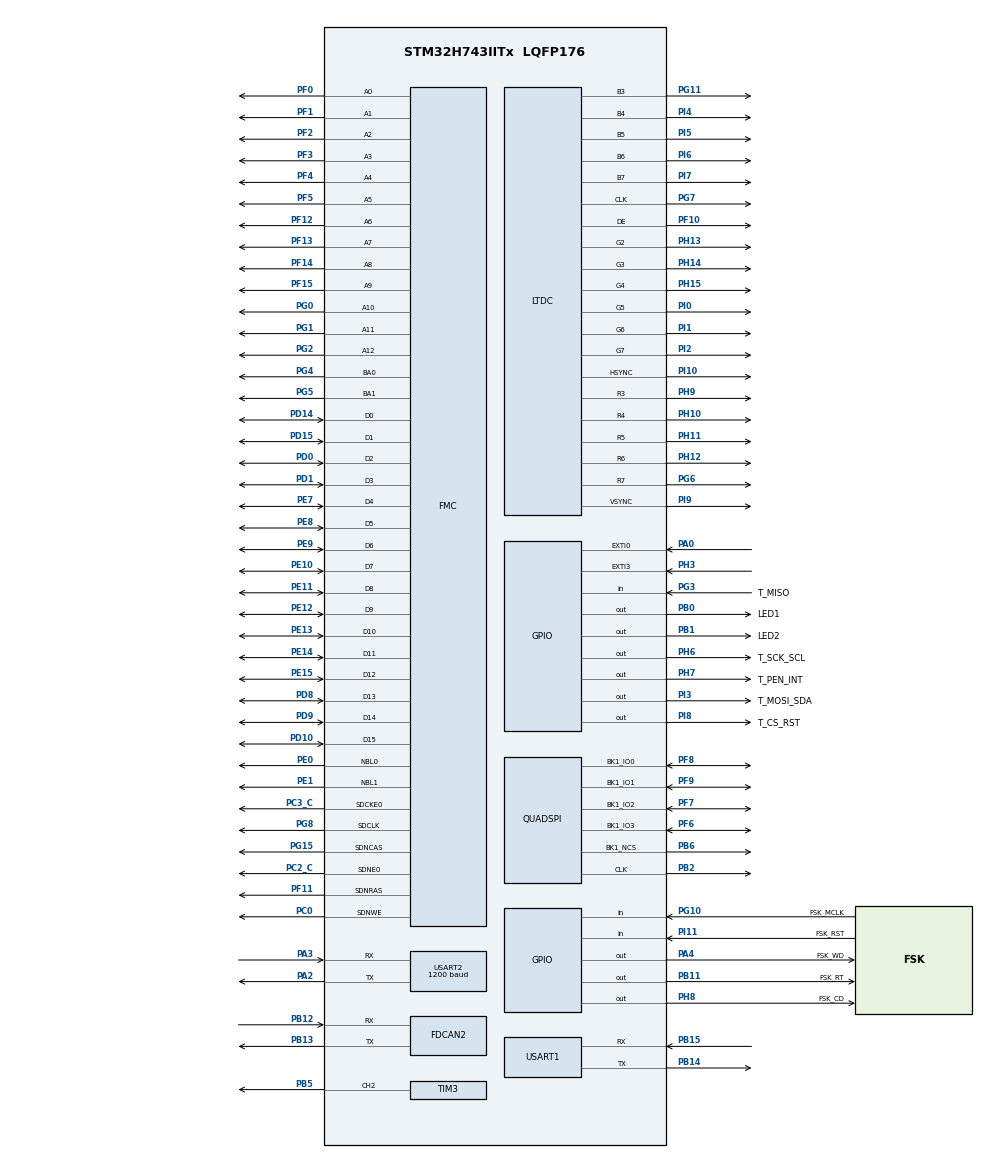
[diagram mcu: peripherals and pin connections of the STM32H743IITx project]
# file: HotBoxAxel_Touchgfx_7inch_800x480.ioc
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CORTEX_M7.AccessPermission-Cortex_Memory_Protection_Unit_Region1_Settings=MPU_REGION_FULL_ACCESS
CORTEX_M7.AccessPermission-Cortex_Memory_Protection_Unit_Region2_Settings=MPU_REGION_FULL_ACCESS
CORTEX_M7.AccessPermission-Cortex_Memory_Protection_Unit_Region3_Settings=MPU_REGION_FULL_ACCESS
CORTEX_M7.AccessPermission-Cortex_Memory_Protection_Unit_Region4_Settings=MPU_REGION_FULL_ACCESS
CORTEX_M7.AccessPermission-Cortex_Memory_Protection_Unit_Region5_Settings=MPU_REGION_FULL_ACCESS
CORTEX_M7.AccessPermission-Cortex_Memory_Protection_Unit_Region6_Settings=MPU_REGION_FULL_ACCESS
CORTEX_M7.AccessPermission-Cortex_Memory_Protection_Unit_Region7_Settings=MPU_REGION_FULL_ACCESS
CORTEX_M7.BaseAddress-Cortex_Memory_Protection_Unit_Region1_Settings=0x90000000
CORTEX_M7.BaseAddress-Cortex_Memory_Protection_Unit_Region2_Settings=0xC0000000
CORTEX_M7.BaseAddress-Cortex_Memory_Protection_Unit_Region3_Settings=0x20000000
CORTEX_M7.BaseAddress-Cortex_Memory_Protection_Unit_Region4_Settings=0x24000000
CORTEX_M7.BaseAddress-Cortex_Memory_Protection_Unit_Region5_Settings=0x30000000
CORTEX_M7.BaseAddress-Cortex_Memory_Protection_Unit_Region6_Settings=0x38000000
CORTEX_M7.BaseAddress-Cortex_Memory_Protection_Unit_Region7_Settings=0x60000000
CORTEX_M7.CPU_DCache=Enabled
CORTEX_M7.CPU_ICache=Enabled
CORTEX_M7.DisableExec-Cortex_Memory_Protection_Unit_Region0_Settings=MPU_INSTRUCTION_ACCESS_DISABLE
CORTEX_M7.DisableExec-Cortex_Memory_Protection_Unit_Region2_Settings=MPU_INSTRUCTION_ACCESS_ENABLE
CORTEX_M7.Enable-Cortex_Memory_Protection_Unit_Region0_Settings=MPU_REGION_ENABLE
CORTEX_M7.Enable-Cortex_Memory_Protection_Unit_Region1_Settings=MPU_REGION_ENABLE
CORTEX_M7.Enable-Cortex_Memory_Protection_Unit_Region2_Settings=MPU_REGION_ENABLE
CORTEX_M7.Enable-Cortex_Memory_Protection_Unit_Region3_Settings=MPU_REGION_ENABLE
CORTEX_M7.Enable-Cortex_Memory_Protection_Unit_Region4_Settings=MPU_REGION_ENABLE
CORTEX_M7.Enable-Cortex_Memory_Protection_Unit_Region5_Settings=MPU_REGION_ENABLE
CORTEX_M7.Enable-Cortex_Memory_Protection_Unit_Region6_Settings=MPU_REGION_ENABLE
CORTEX_M7.Enable-Cortex_Memory_Protection_Unit_Region7_Settings=MPU_REGION_ENABLE
CORTEX_M7.Enable-Cortex_Memory_Protection_Unit_Region8_Settings=__NULL
CORTEX_M7.IsBufferable-Cortex_Memory_Protection_Unit_Region2_Settings=MPU_ACCESS_BUFFERABLE
CORTEX_M7.IsBufferable-Cortex_Memory_Protection_Unit_Region3_Settings=MPU_ACCESS_BUFFERABLE
CORTEX_M7.IsBufferable-Cortex_Memory_Protection_Unit_Region4_Settings=MPU_ACCESS_BUFFERABLE
CORTEX_M7.IsBufferable-Cortex_Memory_Protection_Unit_Region5_Settings=MPU_ACCESS_BUFFERABLE
CORTEX_M7.IsBufferable-Cortex_Memory_Protection_Unit_Region6_Settings=MPU_ACCESS_BUFFERABLE
CORTEX_M7.IsCacheable-Cortex_Memory_Protection_Unit_Region1_Settings=MPU_ACCESS_CACHEABLE
CORTEX_M7.IsCacheable-Cortex_Memory_Protection_Unit_Region2_Settings=MPU_ACCESS_CACHEABLE
CORTEX_M7.IsCacheable-Cortex_Memory_Protection_Unit_Region3_Settings=MPU_ACCESS_CACHEABLE
CORTEX_M7.IsCacheable-Cortex_Memory_Protection_Unit_Region4_Settings=MPU_ACCESS_CACHEABLE
CORTEX_M7.IsCacheable-Cortex_Memory_Protection_Unit_Region5_Settings=MPU_ACCESS_CACHEABLE
CORTEX_M7.IsCacheable-Cortex_Memory_Protection_Unit_Region6_Settings=MPU_ACCESS_CACHEABLE
CORTEX_M7.IsShareable-Cortex_Memory_Protection_Unit_Region0_Settings=MPU_ACCESS_SHAREABLE
CORTEX_M7.MPU_Control=__NULL
CORTEX_M7.Size-Cortex_Memory_Protection_Unit_Region0_Settings=MPU_REGION_SIZE_4GB
CORTEX_M7.Size-Cortex_Memory_Protection_Unit_Region1_Settings=MPU_REGION_SIZE_32MB
CORTEX_M7.Size-Cortex_Memory_Protection_Unit_Region2_Settings=MPU_REGION_SIZE_32MB
CORTEX_M7.Size-Cortex_Memory_Protection_Unit_Region3_Settings=MPU_REGION_SIZE_128KB
CORTEX_M7.Size-Cortex_Memory_Protection_Unit_Region4_Settings=MPU_REGION_SIZE_512KB
CORTEX_M7.Size-Cortex_Memory_Protection_Unit_Region5_Settings=MPU_REGION_SIZE_512KB
CORTEX_M7.Size-Cortex_Memory_Protection_Unit_Region6_Settings=MPU_REGION_SIZE_64KB
CORTEX_M7.Size-Cortex_Memory_Protection_Unit_Region7_Settings=MPU_REGION_SIZE_64KB
CORTEX_M7.SubRegionDisable-Cortex_Memory_Protection_Unit_Region0_Settings=0x87
DMA2D.ColorMode=DMA2D_OUTPUT_RGB565
FDCAN2.CalculateBaudRateNominal=520833
FDCAN2.CalculateTimeBitNominal=1920
FDCAN2.CalculateTimeQuantumNominal=640.0
FMC.CASLatency1=FMC_SDRAM_CAS_LATENCY_3
FMC.ColumnBitsNumber1=FMC_SDRAM_COLUMN_BITS_NUM_9
FMC.ExitSelfRefreshDelay1=7
FMC.LoadToActiveDelay1=2
FMC.RCDDelay1=2
FMC.RPDelay1=2
FMC.ReadBurst1=FMC_SDRAM_RBURST_ENABLE
FMC.ReadPipeDelay1=FMC_SDRAM_RPIPE_DELAY_0
FMC.RowCycleDelay1=7
FMC.SDClockPeriod1=FMC_SDRAM_CLOCK_PERIOD_2
FMC.SelfRefreshTime1=4
FMC.WriteRecoveryTime1=3
LTDC.ActiveW=800
LTDC.Alpha_L0=255
LTDC.BlendingFactor1_L0=LTDC_BLENDING_FACTOR1_CA
LTDC.BlendingFactor2_L0=LTDC_BLENDING_FACTOR2_CA
LTDC.FBStartAdress_L0=0xC0000000
LTDC.HBP=46
LTDC.HFP=198
LTDC.HSync=2
LTDC.ImageHeight_L0=480
LTDC.ImageWidth_L0=800
LTDC.Layers=0
LTDC.PixelFormat_L0=LTDC_PIXEL_FORMAT_RGB565
LTDC.VBP=23
LTDC.VFP=15
LTDC.VSync=2
LTDC.WindowX1_L0=800
LTDC.WindowY1_L0=480
Mcu.Family=STM32H7
Mcu.Name=STM32H743IITx
Mcu.Package=LQFP176
NVIC.DMA2D_IRQn=true\:5\:0\:true\:false\:true\:true\:true\:true
NVIC.EXTI0_IRQn=true\:6\:0\:true\:false\:true\:true\:true\:true
NVIC.EXTI3_IRQn=true\:6\:0\:true\:false\:true\:true\:true\:true
NVIC.LTDC_ER_IRQn=true\:0\:0\:false\:false\:true\:true\:true\:true
NVIC.LTDC_IRQn=true\:5\:0\:true\:false\:true\:true\:true\:true
NVIC.PriorityGroup=NVIC_PRIORITYGROUP_4
NVIC.USART2_IRQn=true\:0\:0\:false\:false\:true\:true\:true\:true
PA0.GPIO_ModeDefaultEXTI=GPIO_MODE_IT_RISING
PA0.Signal=GPXTI0
PA13\ (JTMS/SWDIO).Mode=Serial_Wire
PA13\ (JTMS/SWDIO).Signal=DEBUG_JTMS-SWDIO
PA14\ (JTCK/SWCLK).Mode=Serial_Wire
PA14\ (JTCK/SWCLK).Signal=DEBUG_JTCK-SWCLK
PA2.Mode=Asynchronous
PA2.Signal=USART2_TX
PA3.Mode=Asynchronous
PA3.Signal=USART2_RX
PA4.GPIO_Label=FSK_WD
PA4.Signal=GPIO_Output
PB0.GPIO_Label=LED1
PB0.GPIO_Speed=GPIO_SPEED_FREQ_VERY_HIGH
PB0.PinState=GPIO_PIN_RESET
PB0.Signal=GPIO_Output
PB1.GPIO_Label=LED2
PB1.GPIO_Speed=GPIO_SPEED_FREQ_VERY_HIGH
PB1.Signal=GPIO_Output
PB11.GPIO_Label=FSK_RT
PB11.Signal=GPIO_Output
PB12.GPIO_PuPd=GPIO_PULLUP
PB12.GPIO_Speed=GPIO_SPEED_FREQ_MEDIUM
PB12.Mode=FDCAN_Activate
PB12.Signal=FDCAN2_RX
PB13.Mode=FDCAN_Activate
PB13.Signal=FDCAN2_TX
PB14.Mode=Asynchronous
PB14.Signal=USART1_TX
PB15.Mode=Asynchronous
PB15.Signal=USART1_RX
PB2.GPIO_Speed=GPIO_SPEED_FREQ_VERY_HIGH
PB2.Mode=Single Bank 1
PB2.Signal=QUADSPI_CLK
PB5.Signal=S_TIM3_CH2
PB6.GPIO_FM6=SYSCFG_PMCR_I2C_PB6_FMP
PB6.GPIO_Speed=GPIO_SPEED_FREQ_VERY_HIGH
PB6.Mode=Single Bank 1
PB6.Signal=QUADSPI_BK1_NCS
PC0.Signal=FMC_SDNWE
PC14-OSC32_IN\ (OSC32_IN).Mode=LSE-External-Oscillator
PC14-OSC32_IN\ (OSC32_IN).Signal=RCC_OSC32_IN
PC15-OSC32_OUT\ (OSC32_OUT).Mode=LSE-External-Oscillator
PC15-OSC32_OUT\ (OSC32_OUT).Signal=RCC_OSC32_OUT
PC2_C.Mode=SdramChipSelect1_1
PC2_C.Signal=FMC_SDNE0
PC3_C.Mode=SdramChipSelect1_1
PC3_C.Signal=FMC_SDCKE0
PD0.Signal=FMC_D2_DA2
PD1.Signal=FMC_D3_DA3
PD10.Signal=FMC_D15_DA15
PD11.Signal=FMC_A16_CLE
PD12.Signal=FMC_A17_ALE
PD13.Signal=FMC_A18
PD14.Signal=FMC_D0_DA0
PD15.Signal=FMC_D1_DA1
PD6.Signal=LTDC_B2
PD8.Signal=FMC_D13_DA13
PD9.Signal=FMC_D14_DA14
PE0.Signal=FMC_NBL0
PE1.Signal=FMC_NBL1
PE10.Signal=FMC_D7_DA7
PE11.Signal=FMC_D8_DA8
PE12.Signal=FMC_D9_DA9
PE13.Signal=FMC_D10_DA10
PE14.Signal=FMC_D11_DA11
PE15.Signal=FMC_D12_DA12
PE7.Signal=FMC_D4_DA4
PE8.Signal=FMC_D5_DA5
PE9.Signal=FMC_D6_DA6
PF0.Signal=FMC_A0
PF1.Signal=FMC_A1
PF10.GPIO_Speed=GPIO_SPEED_FREQ_VERY_HIGH
PF10.Mode=RGB565
PF10.Signal=LTDC_DE
PF11.Signal=FMC_SDNRAS
PF12.Signal=FMC_A6
PF13.Signal=FMC_A7
PF14.Signal=FMC_A8
PF15.Signal=FMC_A9
PF2.Signal=FMC_A2
PF3.Signal=FMC_A3
PF4.Signal=FMC_A4
PF5.Signal=FMC_A5
PF6.GPIO_Speed=GPIO_SPEED_FREQ_VERY_HIGH
PF6.Mode=Single Bank 1
PF6.Signal=QUADSPI_BK1_IO3
PF7.GPIO_Speed=GPIO_SPEED_FREQ_VERY_HIGH
PF7.Mode=Single Bank 1
PF7.Signal=QUADSPI_BK1_IO2
PF8.GPIO_Speed=GPIO_SPEED_FREQ_VERY_HIGH
PF8.Mode=Single Bank 1
PF8.Signal=QUADSPI_BK1_IO0
PF9.GPIO_Speed=GPIO_SPEED_FREQ_VERY_HIGH
PF9.Mode=Single Bank 1
PF9.Signal=QUADSPI_BK1_IO1
PG0.Signal=FMC_A10
PG1.Signal=FMC_A11
PG10.GPIO_Label=FSK_MCLK
PG10.Signal=GPIO_Input
PG11.GPIO_Speed=GPIO_SPEED_FREQ_VERY_HIGH
PG11.Mode=RGB565
PG11.Signal=LTDC_B3
PG12.Signal=LTDC_B1
PG14.Signal=LTDC_B0
PG15.Signal=FMC_SDNCAS
PG2.Signal=FMC_A12
PG3.GPIO_Label=T_MISO
PG3.GPIO_PuPd=GPIO_NOPULL
PG3.Signal=GPIO_Input
PG4.Signal=FMC_A14_BA0
PG5.Signal=FMC_A15_BA1
PG6.GPIO_Speed=GPIO_SPEED_FREQ_VERY_HIGH
PG6.Mode=RGB565
PG6.Signal=LTDC_R7
PG7.GPIO_Speed=GPIO_SPEED_FREQ_VERY_HIGH
PG7.Mode=RGB565
PG7.Signal=LTDC_CLK
PG8.Signal=FMC_SDCLK
PH0-OSC_IN\ (PH0).Mode=HSE-External-Oscillator
PH0-OSC_IN\ (PH0).Signal=RCC_OSC_IN
PH1-OSC_OUT\ (PH1).Mode=HSE-External-Oscillator
PH1-OSC_OUT\ (PH1).Signal=RCC_OSC_OUT
PH10.GPIO_Speed=GPIO_SPEED_FREQ_VERY_HIGH
PH10.Mode=RGB565
PH10.Signal=LTDC_R4
PH11.GPIO_Speed=GPIO_SPEED_FREQ_VERY_HIGH
PH11.Mode=RGB565
PH11.Signal=LTDC_R5
PH12.GPIO_Speed=GPIO_SPEED_FREQ_VERY_HIGH
PH12.Mode=RGB565
PH12.Signal=LTDC_R6
PH13.GPIO_Speed=GPIO_SPEED_FREQ_VERY_HIGH
PH13.Mode=RGB565
PH13.Signal=LTDC_G2
PH14.GPIO_Speed=GPIO_SPEED_FREQ_VERY_HIGH
PH14.Mode=RGB565
PH14.Signal=LTDC_G3
PH15.GPIO_Speed=GPIO_SPEED_FREQ_VERY_HIGH
PH15.Mode=RGB565
PH15.Signal=LTDC_G4
PH3.GPIO_ModeDefaultEXTI=GPIO_MODE_IT_FALLING
PH3.Signal=GPXTI3
PH6.GPIO_Label=T_SCK_SCL
PH6.GPIO_ModeDefaultOutputPP=GPIO_MODE_OUTPUT_OD
PH6.GPIO_PuPd=GPIO_NOPULL
PH6.GPIO_Speed=GPIO_SPEED_FREQ_LOW
PH6.PinState=GPIO_PIN_SET
PH6.Signal=GPIO_Output
PH7.GPIO_Label=T_PEN_INT
PH7.GPIO_PuPd=GPIO_NOPULL
PH7.Signal=GPIO_Output
PH8.GPIO_Label=FSK_CD
PH8.Signal=GPIO_Output
PH9.GPIO_Speed=GPIO_SPEED_FREQ_VERY_HIGH
PH9.Mode=RGB565
PH9.Signal=LTDC_R3
PI0.GPIO_Speed=GPIO_SPEED_FREQ_VERY_HIGH
PI0.Mode=RGB565
PI0.Signal=LTDC_G5
PI1.GPIO_Speed=GPIO_SPEED_FREQ_VERY_HIGH
PI1.Mode=RGB565
PI1.Signal=LTDC_G6
PI10.GPIO_Speed=GPIO_SPEED_FREQ_VERY_HIGH
PI10.Mode=RGB565
PI10.Signal=LTDC_HSYNC
PI11.GPIO_Label=FSK_RST
PI11.Signal=GPIO_Input
PI2.GPIO_Speed=GPIO_SPEED_FREQ_VERY_HIGH
PI2.Mode=RGB565
PI2.Signal=LTDC_G7
PI3.GPIO_Label=T_MOSI_SDA
PI3.GPIO_ModeDefaultOutputPP=GPIO_MODE_OUTPUT_OD
PI3.GPIO_PuPd=GPIO_NOPULL
PI3.GPIO_Speed=GPIO_SPEED_FREQ_LOW
PI3.PinState=GPIO_PIN_RESET
PI3.Signal=GPIO_Output
PI4.GPIO_Speed=GPIO_SPEED_FREQ_VERY_HIGH
PI4.Mode=RGB565
PI4.Signal=LTDC_B4
PI5.GPIO_Speed=GPIO_SPEED_FREQ_VERY_HIGH
PI5.Mode=RGB565
PI5.Signal=LTDC_B5
PI6.GPIO_Speed=GPIO_SPEED_FREQ_VERY_HIGH
PI6.Mode=RGB565
PI6.Signal=LTDC_B6
PI7.GPIO_Speed=GPIO_SPEED_FREQ_VERY_HIGH
PI7.Mode=RGB565
PI7.Signal=LTDC_B7
PI8.GPIO_Label=T_CS_RST
PI8.Signal=GPIO_Output
PI9.GPIO_Speed=GPIO_SPEED_FREQ_VERY_HIGH
PI9.Mode=RGB565
PI9.Signal=LTDC_VSYNC
ProjectManager.HeapSize=0x1000
ProjectManager.StackSize=0x2000
ProjectManager.TargetToolchain=STM32CubeIDE
QUADSPI.ClockMode=QSPI_CLOCK_MODE_3
QUADSPI.ClockPrescaler=4
QUADSPI.FifoThreshold=4
QUADSPI.FlashSize=22
QUADSPI.SampleShifting=QSPI_SAMPLE_SHIFTING_HALFCYCLE
RCC.ADCFreq_Value=133000000
RCC.APB1Freq_Value=60000000
RCC.APB2Freq_Value=120000000
RCC.APB3Freq_Value=120000000
RCC.APB4Freq_Value=120000000
RCC.CortexFreq_Value=480000000
RCC.D1PPRE=RCC_APB3_DIV2
RCC.D2PPRE1=RCC_APB1_DIV4
RCC.D2PPRE2=RCC_APB2_DIV2
RCC.D3PPRE=RCC_APB4_DIV2
RCC.DIVM1=5
RCC.DIVM2=25
RCC.DIVM3=25
RCC.DIVN1=192
RCC.DIVN2=266
RCC.DIVN3=330
RCC.DIVQ1=10
RCC.DIVR3=10
RCC.FDCANCLockSelection=RCC_FDCANCLKSOURCE_HSE
RCC.FMCCLockSelection=RCC_FMCCLKSOURCE_PLL2
RCC.HCLKFreq_Value=240000000
RCC.HPRE=RCC_HCLK_DIV2
RCC.PLL1_VCI_Range-AdvancedSettings=RCC_PLL1VCIRANGE_1
RCC.PLL2FRACN=0
RCC.PLL2_VCI_Range-AdvancedSettings=RCC_PLL2VCIRANGE_3
RCC.PLL3FRACN=0
RCC.PLLFRACN=0
RCC.PLLSourceVirtual=RCC_PLLSOURCE_HSE
RCC.PWR_Regulator_Voltage_Scale=PWR_REGULATOR_VOLTAGE_SCALE0
RCC.QSPICLockSelection=RCC_QSPICLKSOURCE_PLL
RCC.RTCClockSelection=RCC_RTCCLKSOURCE_LSE
RCC.SYSCLKFreq_VALUE=480000000
RCC.SYSCLKSource=RCC_SYSCLKSOURCE_PLLCLK
RCC.USBFreq_Value=96000000
SH.FMC_A0.0=FMC_A0,13b-sda1
SH.FMC_A1.0=FMC_A1,13b-sda1
SH.FMC_A10.0=FMC_A10,13b-sda1
SH.FMC_A11.0=FMC_A11,13b-sda1
SH.FMC_A12.0=FMC_A12,13b-sda1
SH.FMC_A14_BA0.0=FMC_BA0,FourSdramBanks1
SH.FMC_A15_BA1.0=FMC_BA1,FourSdramBanks1
SH.FMC_A16_CLE.0=FMC_CLE
SH.FMC_A16_CLE.1=FMC_A16
SH.FMC_A17_ALE.0=FMC_A17
SH.FMC_A17_ALE.1=FMC_ALE
SH.FMC_A18.0=FMC_A18
SH.FMC_A2.0=FMC_A2,13b-sda1
SH.FMC_A3.0=FMC_A3,13b-sda1
SH.FMC_A4.0=FMC_A4,13b-sda1
SH.FMC_A5.0=FMC_A5,13b-sda1
SH.FMC_A6.0=FMC_A6,13b-sda1
SH.FMC_A7.0=FMC_A7,13b-sda1
SH.FMC_A8.0=FMC_A8,13b-sda1
SH.FMC_A9.0=FMC_A9,13b-sda1
SH.FMC_D0_DA0.0=FMC_D0,sd-16b-d1
SH.FMC_D10_DA10.0=FMC_D10,sd-16b-d1
SH.FMC_D11_DA11.0=FMC_D11,sd-16b-d1
SH.FMC_D12_DA12.0=FMC_D12,sd-16b-d1
SH.FMC_D13_DA13.0=FMC_D13,sd-16b-d1
SH.FMC_D14_DA14.0=FMC_D14,sd-16b-d1
SH.FMC_D15_DA15.0=FMC_D15,sd-16b-d1
SH.FMC_D1_DA1.0=FMC_D1,sd-16b-d1
SH.FMC_D2_DA2.0=FMC_D2,sd-16b-d1
SH.FMC_D3_DA3.0=FMC_D3,sd-16b-d1
SH.FMC_D4_DA4.0=FMC_D4,sd-16b-d1
SH.FMC_D5_DA5.0=FMC_D5,sd-16b-d1
SH.FMC_D6_DA6.0=FMC_D6,sd-16b-d1
SH.FMC_D7_DA7.0=FMC_D7,sd-16b-d1
SH.FMC_D8_DA8.0=FMC_D8,sd-16b-d1
SH.FMC_D9_DA9.0=FMC_D9,sd-16b-d1
SH.FMC_NBL0.0=FMC_NBL0,Sd2ByteEnable1
SH.FMC_NBL1.0=FMC_NBL1,Sd2ByteEnable1
SH.FMC_SDCLK.0=FMC_SDCLK,13b-sda1
SH.FMC_SDNCAS.0=FMC_SDNCAS,13b-sda1
SH.FMC_SDNRAS.0=FMC_SDNRAS,13b-sda1
SH.FMC_SDNWE.0=FMC_SDNWE,13b-sda1
SH.S_TIM3_CH2.0=TIM3_CH2,PWM Generation2 CH2
STMicroelectronics.X-CUBE-TOUCHGFX.4.25.0.ApplicationCcGraphicsJjApplication=TouchGFXOoGenerator
STMicroelectronics.X-CUBE-TOUCHGFX.4.25.0.tgfx_address1=0xC0000000
STMicroelectronics.X-CUBE-TOUCHGFX.4.25.0.tgfx_address2=0xC00BC800
STMicroelectronics.X-CUBE-TOUCHGFX.4.25.0.tgfx_buffering_strategy=Double
STMicroelectronics.X-CUBE-TOUCHGFX.4.25.0.tgfx_display_interface=disp_ltdc
STMicroelectronics.X-CUBE-TOUCHGFX.4.25.0.tgfx_framebuffer_stride=Disabled
STMicroelectronics.X-CUBE-TOUCHGFX.4.25.0.tgfx_hardware_accelerator=dma_2d
STMicroelectronics.X-CUBE-TOUCHGFX.4.25.0.tgfx_location=By Address
STMicroelectronics.X-CUBE-TOUCHGFX.4.25.0.tgfx_vsync=vsync_ltdc
STMicroelectronics.X-CUBE-TOUCHGFX.4.25.0_IsPackSelfContextualization=true
TIM3.Channel-PWM\ Generation2\ CH2=TIM_CHANNEL_2
TIM3.Period=240-1
TIM3.Prescaler=1000-1
USART1.VirtualMode-Asynchronous=VM_ASYNC
USART2.BaudRate=1200
USART2.RxPinLevelInvertParam=ADVFEATURE_RXINV_DISABLE
USART2.SwapParam=ADVFEATURE_SWAP_DISABLE
USART2.VirtualMode-Asynchronous=VM_ASYNC
VP_CRC_VS_CRC.Mode=CRC_Activate
VP_DMA2D_VS_DMA2D.Mode=DMA2D_Activate
VP_MEMORYMAP_VS_MEMORYMAP.Mode=CurAppReg
VP_RTC_VS_RTC_Activate.Mode=RTC_Enabled
VP_STMicroelectronics.X-CUBE-TOUCHGFX_VS_GraphicsJjApplication_4.25.0.Mode=GraphicsJjApplication
board=custom

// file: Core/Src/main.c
/* USER CODE BEGIN Header */
/**
  ******************************************************************************
  * @file           : main.c
  * @brief          : Main program body
  ******************************************************************************
  * @attention
  *
  * Copyright (c) 2024 STMicroelectronics.
  * All rights reserved.
  *
  * This software is licensed under terms that can be found in the LICENSE file
  * in the root directory of this software component.
  * If no LICENSE file comes with this software, it is provided AS-IS.
  *
  ******************************************************************************
  */
/* USER CODE END Header */
#include "main.h"
#include "crc.h"
#include "dma2d.h"
#include "fdcan.h"
#include "ltdc.h"
#include "quadspi.h"
#include "rtc.h"
#include "tim.h"
#include "usart.h"
#include "gpio.h"
#include "fmc.h"
#include "app_touchgfx.h"

/* USER CODE BEGIN Includes */
#include "W25Q64_QSPI.h"
/* USER CODE END Includes */

/* USER CODE BEGIN PV */
__IO uint8_t User_ButtonState0=0;
__IO uint8_t User_ButtonState1=0;
/* USER CODE END PV */

void SystemClock_Config(void);
/* USER CODE BEGIN PFP */
void MPU_Config(void);
/* USER CODE END PFP */

/* USER CODE BEGIN 0 */
void HAL_GPIO_EXTI_Callback(uint16_t GPIO_Pin)
{
	if(GPIO_Pin==GPIO_PIN_0)
	{
		User_ButtonState1=1; //Key2
	}
	if(GPIO_Pin==GPIO_PIN_3)
	{
		User_ButtonState0=1; //Key1
	}

}
/* USER CODE END 0 */

int main(void)
{

  /* USER CODE BEGIN 1 */
	MPU_Config();
  /* USER CODE END 1 */

  /* Enable the CPU Cache */

  /* Enable I-Cache---------------------------------------------------------*/
  SCB_EnableICache();

  /* Enable D-Cache---------------------------------------------------------*/
  SCB_EnableDCache();

  /* MCU Configuration--------------------------------------------------------*/

  /* Reset of all peripherals, Initializes the Flash interface and the Systick. */
  HAL_Init();

  /* Configure the system clock */
  SystemClock_Config();

  /* Initialize all configured peripherals */
  MX_GPIO_Init();
  MX_DMA2D_Init();
  MX_FMC_Init();
  MX_LTDC_Init();
  MX_CRC_Init();
  MX_FDCAN2_Init();
  MX_USART1_UART_Init();
  MX_QUADSPI_Init();
  MX_RTC_Init();
  MX_TIM3_Init();
  MX_USART2_UART_Init();
  MX_TouchGFX_Init();
  /* USER CODE BEGIN 2 */
  HAL_GPIO_WritePin(FSK_WD_GPIO_Port, FSK_WD_Pin, GPIO_PIN_RESET);
  HAL_GPIO_WritePin(FSK_RT_GPIO_Port, FSK_RT_Pin, GPIO_PIN_SET); //Read Mode
  HAL_GPIO_WritePin(FSK_CD_GPIO_Port, FSK_CD_Pin, GPIO_PIN_SET);
  /* USER CODE END 2 */

  /* Infinite loop */
  /* USER CODE BEGIN WHILE */
  uint16_t *lcd_address=(uint16_t *)SDRAM_BANK_ADDR;
  for(int i=0;i<800*480;i++)
  {
	  *lcd_address=0x0000;
	  lcd_address++;
  }
  HAL_Delay(300);
  HAL_TIM_PWM_Start(&htim3, TIM_CHANNEL_2);
  while (1)
  {
    /* USER CODE END WHILE */

  MX_TouchGFX_Process();
  }
}

void SystemClock_Config(void)
{
  RCC_OscInitTypeDef RCC_OscInitStruct = {0};
  RCC_ClkInitTypeDef RCC_ClkInitStruct = {0};

  /** Supply configuration update enable
  */
  HAL_PWREx_ConfigSupply(PWR_LDO_SUPPLY);

  /** Configure the main internal regulator output voltage
  */
  __HAL_PWR_VOLTAGESCALING_CONFIG(PWR_REGULATOR_VOLTAGE_SCALE0);

  while(!__HAL_PWR_GET_FLAG(PWR_FLAG_VOSRDY)) {}

  /** Configure LSE Drive Capability
  */
  HAL_PWR_EnableBkUpAccess();
  __HAL_RCC_LSEDRIVE_CONFIG(RCC_LSEDRIVE_LOW);

  /** Initializes the RCC Oscillators according to the specified parameters
  * in the RCC_OscInitTypeDef structure.
  */
  RCC_OscInitStruct.OscillatorType = RCC_OSCILLATORTYPE_HSE|RCC_OSCILLATORTYPE_LSE;
  RCC_OscInitStruct.HSEState = RCC_HSE_ON;
  RCC_OscInitStruct.LSEState = RCC_LSE_ON;
  RCC_OscInitStruct.PLL.PLLState = RCC_PLL_ON;
  RCC_OscInitStruct.PLL.PLLSource = RCC_PLLSOURCE_HSE;
  RCC_OscInitStruct.PLL.PLLM = 5;
  RCC_OscInitStruct.PLL.PLLN = 192;
  RCC_OscInitStruct.PLL.PLLP = 2;
  RCC_OscInitStruct.PLL.PLLQ = 10;
  RCC_OscInitStruct.PLL.PLLR = 2;
  RCC_OscInitStruct.PLL.PLLRGE = RCC_PLL1VCIRANGE_2;
  RCC_OscInitStruct.PLL.PLLVCOSEL = RCC_PLL1VCOWIDE;
  RCC_OscInitStruct.PLL.PLLFRACN = 0;
  if (HAL_RCC_OscConfig(&RCC_OscInitStruct) != HAL_OK)
  {
    Error_Handler();
  }

  /** Initializes the CPU, AHB and APB buses clocks
  */
  RCC_ClkInitStruct.ClockType = RCC_CLOCKTYPE_HCLK|RCC_CLOCKTYPE_SYSCLK
                              |RCC_CLOCKTYPE_PCLK1|RCC_CLOCKTYPE_PCLK2
                              |RCC_CLOCKTYPE_D3PCLK1|RCC_CLOCKTYPE_D1PCLK1;
  RCC_ClkInitStruct.SYSCLKSource = RCC_SYSCLKSOURCE_PLLCLK;
  RCC_ClkInitStruct.SYSCLKDivider = RCC_SYSCLK_DIV1;
  RCC_ClkInitStruct.AHBCLKDivider = RCC_HCLK_DIV2;
  RCC_ClkInitStruct.APB3CLKDivider = RCC_APB3_DIV2;
  RCC_ClkInitStruct.APB1CLKDivider = RCC_APB1_DIV4;
  RCC_ClkInitStruct.APB2CLKDivider = RCC_APB2_DIV2;
  RCC_ClkInitStruct.APB4CLKDivider = RCC_APB4_DIV2;

  if (HAL_RCC_ClockConfig(&RCC_ClkInitStruct, FLASH_LATENCY_4) != HAL_OK)
  {
    Error_Handler();
  }
}

/* USER CODE BEGIN 4 */
void MPU_Config(void)
{
	MPU_Region_InitTypeDef MPU_InitStruct;

	HAL_MPU_Disable(); // Disable first MPU

	MPU_InitStruct.Enable           = MPU_REGION_ENABLE;
	MPU_InitStruct.BaseAddress      = SDRAM_BANK_ADDR;
	MPU_InitStruct.Size             = MPU_REGION_SIZE_32MB;
	MPU_InitStruct.AccessPermission = MPU_REGION_FULL_ACCESS;
	MPU_InitStruct.IsBufferable     = MPU_ACCESS_NOT_BUFFERABLE;
	MPU_InitStruct.IsCacheable      = MPU_ACCESS_CACHEABLE;
	MPU_InitStruct.IsShareable      = MPU_ACCESS_NOT_SHAREABLE;
	MPU_InitStruct.Number           = MPU_REGION_NUMBER2;
	MPU_InitStruct.TypeExtField     = MPU_TEX_LEVEL0;
	MPU_InitStruct.SubRegionDisable = 0x00;
	MPU_InitStruct.DisableExec      = MPU_INSTRUCTION_ACCESS_ENABLE;

	HAL_MPU_ConfigRegion(&MPU_InitStruct);

	HAL_MPU_Enable(MPU_PRIVILEGED_DEFAULT); // Enable MPU
}

/* USER CODE END 4 */

void Error_Handler(void)
{
  __disable_irq();
  while (1)
  {
  }
}
